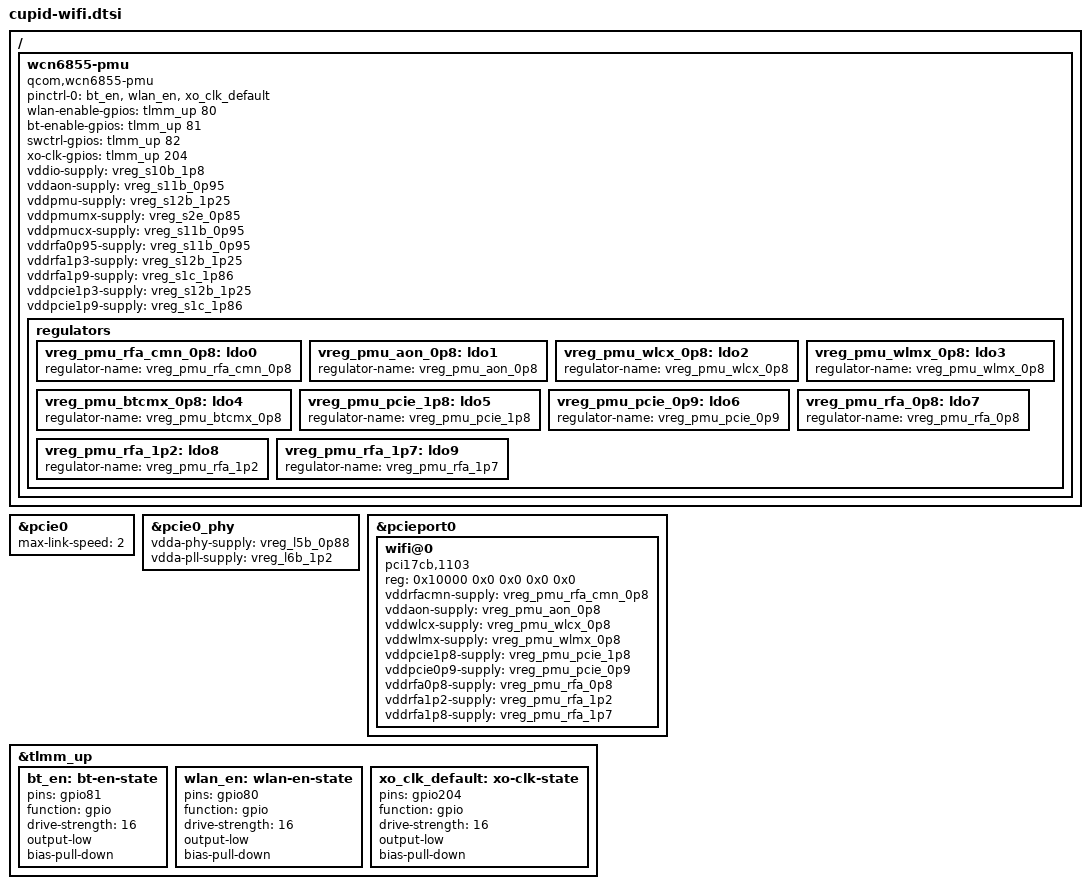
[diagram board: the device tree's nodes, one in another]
/* ===== CUPID_WIFI_ENABLE (v61): QCA6490 on pcie0 + WCN6855 PMU ===== */
/ {
	wcn6855-pmu {
		compatible = "qcom,wcn6855-pmu";

		pinctrl-0 = <&bt_en>, <&wlan_en>, <&xo_clk_default>;
		pinctrl-names = "default";

		wlan-enable-gpios = <&tlmm_up 80 GPIO_ACTIVE_HIGH>;
		bt-enable-gpios = <&tlmm_up 81 GPIO_ACTIVE_HIGH>;
		swctrl-gpios = <&tlmm_up 82 GPIO_ACTIVE_HIGH>;
		xo-clk-gpios = <&tlmm_up 204 GPIO_ACTIVE_HIGH>;

		vddio-supply = <&vreg_s10b_1p8>;
		vddaon-supply = <&vreg_s11b_0p95>;
		vddpmu-supply = <&vreg_s12b_1p25>;
		vddpmumx-supply = <&vreg_s2e_0p85>;
		vddpmucx-supply = <&vreg_s11b_0p95>;
		vddrfa0p95-supply = <&vreg_s11b_0p95>;
		vddrfa1p3-supply = <&vreg_s12b_1p25>;
		vddrfa1p9-supply = <&vreg_s1c_1p86>;
		vddpcie1p3-supply = <&vreg_s12b_1p25>;
		vddpcie1p9-supply = <&vreg_s1c_1p86>;

		regulators {
			vreg_pmu_rfa_cmn_0p8: ldo0 {
				regulator-name = "vreg_pmu_rfa_cmn_0p8";
			};

			vreg_pmu_aon_0p8: ldo1 {
				regulator-name = "vreg_pmu_aon_0p8";
			};

			vreg_pmu_wlcx_0p8: ldo2 {
				regulator-name = "vreg_pmu_wlcx_0p8";
			};

			vreg_pmu_wlmx_0p8: ldo3 {
				regulator-name = "vreg_pmu_wlmx_0p8";
			};

			vreg_pmu_btcmx_0p8: ldo4 {
				regulator-name = "vreg_pmu_btcmx_0p8";
			};

			vreg_pmu_pcie_1p8: ldo5 {
				regulator-name = "vreg_pmu_pcie_1p8";
			};

			vreg_pmu_pcie_0p9: ldo6 {
				regulator-name = "vreg_pmu_pcie_0p9";
			};

			vreg_pmu_rfa_0p8: ldo7 {
				regulator-name = "vreg_pmu_rfa_0p8";
			};

			vreg_pmu_rfa_1p2: ldo8 {
				regulator-name = "vreg_pmu_rfa_1p2";
			};

			vreg_pmu_rfa_1p7: ldo9 {
				regulator-name = "vreg_pmu_rfa_1p7";
			};
		};
	};
};

&pcie0 {
	status = "okay";
	max-link-speed = <2>;
};

&pcie0_phy {
	status = "okay";
	vdda-phy-supply = <&vreg_l5b_0p88>;
	vdda-pll-supply = <&vreg_l6b_1p2>;
};

&pcieport0 {
	wifi@0 {
		compatible = "pci17cb,1103";
		reg = <0x10000 0x0 0x0 0x0 0x0>;

		vddrfacmn-supply = <&vreg_pmu_rfa_cmn_0p8>;
		vddaon-supply = <&vreg_pmu_aon_0p8>;
		vddwlcx-supply = <&vreg_pmu_wlcx_0p8>;
		vddwlmx-supply = <&vreg_pmu_wlmx_0p8>;
		vddpcie1p8-supply = <&vreg_pmu_pcie_1p8>;
		vddpcie0p9-supply = <&vreg_pmu_pcie_0p9>;
		vddrfa0p8-supply = <&vreg_pmu_rfa_0p8>;
		vddrfa1p2-supply = <&vreg_pmu_rfa_1p2>;
		vddrfa1p8-supply = <&vreg_pmu_rfa_1p7>;
	};
};

&tlmm_up {
	bt_en: bt-en-state {
		pins = "gpio81";
		function = "gpio";
		drive-strength = <16>;
		output-low;
		bias-pull-down;
	};

	wlan_en: wlan-en-state {
		pins = "gpio80";
		function = "gpio";
		drive-strength = <16>;
		output-low;
		bias-pull-down;
	};

	xo_clk_default: xo-clk-state {
		pins = "gpio204";
		function = "gpio";
		drive-strength = <16>;
		output-low;
		bias-pull-down;
	};
};
